# CPU_ITM register map
Vendor: Texas Instruments
Peripheral module from a debugger description file (folder CC26x4).
Registers are 32-bit, read-only, reset 0x0 unless marked. A register's access mark holds for its fields unless they carry their own. Offsets are as the file gives them; lines under a group give offsets from that group; [hi:lo] are bit positions; {n}, {i} and the like mark numbered series; 'fields as' and 'values as' point back to an identical list; <NAME> marks a mode.

## CPU_ITM — Cortex-M's Instrumentation Trace Macrocell (ITM)
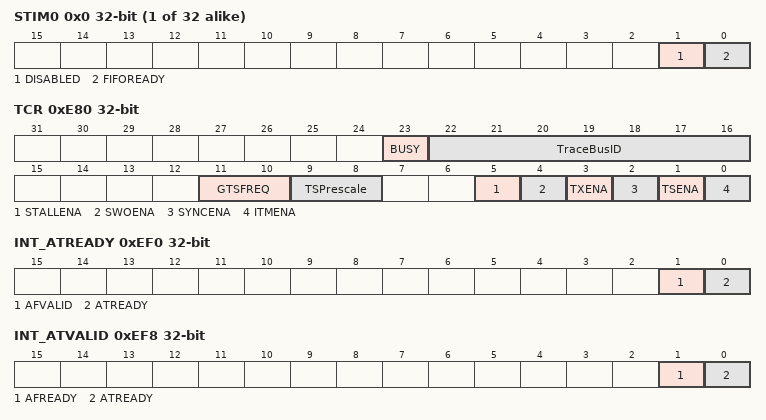
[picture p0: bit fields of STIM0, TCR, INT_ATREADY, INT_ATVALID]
{0x0+4i} STIM{i} (i=0..31) — Provides the interface for generating Instrumentation packets
  [1] DISABLED — Indicates whether the Stimulus Port is enabled or disabled
  [0] FIFOREADY — Indicates whether the Stimulus Port can accept data
0xE00 TER0 rw — Provide an individual enable bit for each ITM_STIM register
  [31:0] STIMENA — For STIMENA[m] in ITM_TER*n, controls whether ITM_STIM(32*n + m) is enabled
0xE40 TPR rw — Controls which stimulus ports can be accessed by unprivileged code
  [31:0] PRIVMASK — For PRIVMASK[m], defines the access permissions of ITM_STIM Stimulus Ports 8m to 8m+7 inclusive
0xE80 TCR access per field — Configures and controls transfers through the ITM interface
  [23] BUSY ro — Indicates whether the ITM is currently processing events
  [22:16] TraceBusID rw — Identifier for multi-source trace stream formatting. If multi-source trace is in use, the debugger must write a unique non-zero trace ID value to this field
  [11:10] GTSFREQ rw — Defines how often the ITM generates a global timestamp, based on the global timestamp clock frequency, or disables generation of global timestamps
  [9:8] TSPrescale rw — Local timestamp prescaler, used with the trace packet reference clock
  [5] STALLENA rw — Stall the PE to guarantee delivery of Data Trace packets.
  [4] SWOENA rw — Enables asynchronous clocking of the timestamp counter
  [3] TXENA rw — Enables forwarding of hardware event packet from the DWT unit to the ITM for output to the TPIU
  [2] SYNCENA rw — Enables Synchronization packet transmission for a synchronous TPIU
  [1] TSENA rw — Enables Local timestamp generation
  [0] ITMENA rw — Enables the ITM
0xEF0 INT_ATREADY — Integration Mode: Read ATB Ready
  [1] AFVALID — A read of this bit returns the value of AFVALID
  [0] ATREADY — A read of this bit returns the value of ATREADY
0xEF8 INT_ATVALID access per field — Integration Mode: Write ATB Valid
  [1] AFREADY wo — A write to this bit gives the value of AFREADY
  [0] ATREADY wo — A write to this bit gives the value of ATVALID
0xF00 ITCTRL access per field — Integration Mode Control Register
  [0] IME rw — Integration mode enable bit - The possible values are: 0 - The trace unit is not in integration mode. 1 - The trace unit is in integration mode. This mode enables: A debug agent to perform topology detection. SoC test software to perform integration testing.
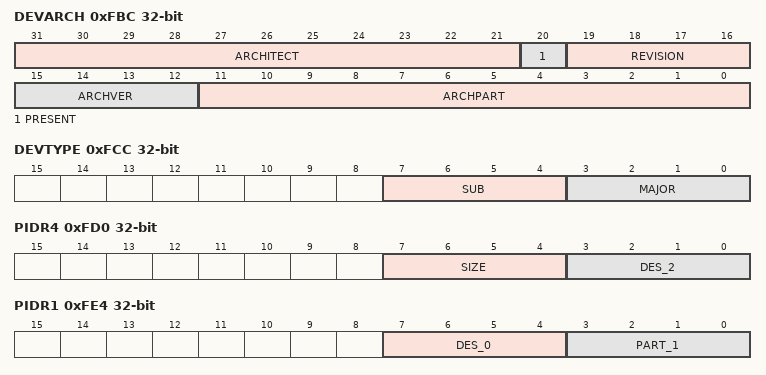
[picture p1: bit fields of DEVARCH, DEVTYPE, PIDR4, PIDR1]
0xFBC DEVARCH — Provides CoreSight discovery information for the ITM
  [31:21] ARCHITECT — Defines the architect of the component. Bits [31:28] are the JEP106 continuation code (JEP106 bank ID, minus 1) and bits [27:21] are the JEP106 ID code.
  [20] PRESENT — Defines that the DEVARCH register is present
  [19:16] REVISION — Defines the architecture revision of the component
  [15:12] ARCHVER — Defines the architecture version of the component
  [11:0] ARCHPART — Defines the architecture of the component
0xFCC DEVTYPE — Provides CoreSight discovery information for the ITM
  [7:4] SUB — Component sub-type
  [3:0] MAJOR — Component major type
0xFD0 PIDR4 — Provides CoreSight discovery information for the ITM
  [7:4] SIZE — See CoreSight Architecture Specification
  [3:0] DES_2 — See CoreSight Architecture Specification
{0xFC0+4i} PIDR{i} (i=5..7) — Provides CoreSight discovery information for the ITM
0xFE0 PIDR0 — Provides CoreSight discovery information for the ITM
  [7:0] PART_0 — See CoreSight Architecture Specification
0xFE4 PIDR1 — Provides CoreSight discovery information for the ITM
  [7:4] DES_0 — See CoreSight Architecture Specification
  [3:0] PART_1 — See CoreSight Architecture Specification
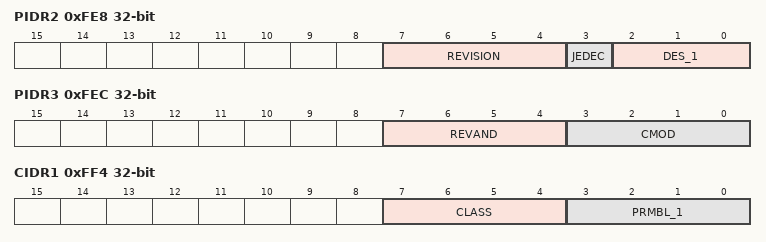
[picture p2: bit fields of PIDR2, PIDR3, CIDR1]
0xFE8 PIDR2 — Provides CoreSight discovery information for the ITM
  [7:4] REVISION — See CoreSight Architecture Specification
  [3] JEDEC — See CoreSight Architecture Specification
  [2:0] DES_1 — See CoreSight Architecture Specification
0xFEC PIDR3 — Provides CoreSight discovery information for the ITM
  [7:4] REVAND — See CoreSight Architecture Specification
  [3:0] CMOD — See CoreSight Architecture Specification
0xFF0 CIDR0 — Provides CoreSight discovery information for the ITM
  [7:0] PRMBL_0 — See CoreSight Architecture Specification
0xFF4 CIDR1 — Provides CoreSight discovery information for the ITM
  [7:4] CLASS — See CoreSight Architecture Specification
  [3:0] PRMBL_1 — See CoreSight Architecture Specification
0xFF8 CIDR2 — Provides CoreSight discovery information for the ITM
  [7:0] PRMBL_2 — See CoreSight Architecture Specification
0xFFC CIDR3 — Provides CoreSight discovery information for the ITM
  [7:0] PRMBL_3 — See CoreSight Architecture Specification
